AUTOSAR XML (schema 00048)
package /AdaptiveApplicationSwComponentTypes
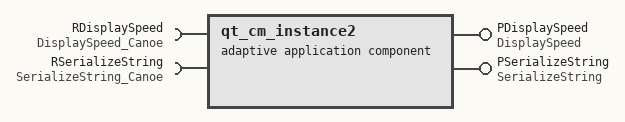
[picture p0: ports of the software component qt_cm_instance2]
  adaptive application sw component type qt_cm_instance2
    provide port PDisplaySpeed: provided-interface=DisplaySpeed
    require port RDisplaySpeed: required-interface=DisplaySpeed_Canoe
    require port RSerializeString: required-interface=SerializeString_Canoe
    provide port PSerializeString: provided-interface=SerializeString
package /Executables
  executable qt_cm_instance2
    root sw component prototype rootSwComponentPrototype: application-type=qt_cm_instance2
